# APM32F411 register map
Vendor: Geehy; File version: 2024.11.05
CPU: CM4 r1p0, little endian, 3 interrupt priority bits
Registers are 32-bit, read-write, reset 0x0 unless marked. A register's access mark holds for its fields unless they carry their own. Offsets are from the block's base; [hi:lo] are bit positions.

## TMR10 — General-purpose-timers
Base 0x40014400
Same registers: TMR13 0x40001C00, TMR14 0x40002000
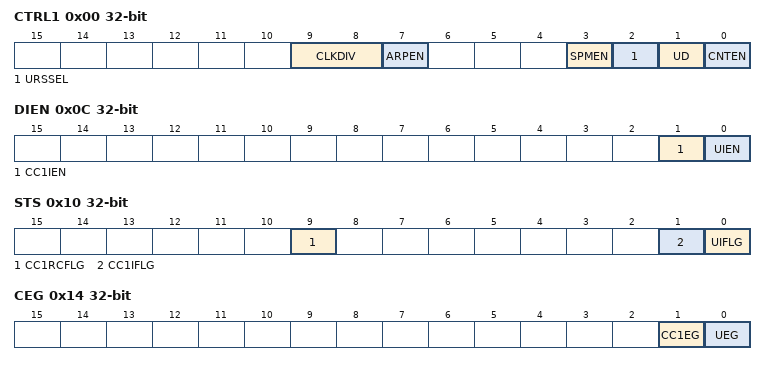
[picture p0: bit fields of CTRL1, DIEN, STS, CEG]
0x00 CTRL1 — control register 1
  [9:8] CLKDIV — Clock division
  [7] ARPEN — Auto-reload preload enable
  [3] SPMEN — Single Pulse Mode Enable
  [2] URSSEL — Update request source
  [1] UD — Update disable
  [0] CNTEN — Counter enable
0x0C DIEN — DMA/Interrupt enable register
  [1] CC1IEN — Capture/Compare 1 interrupt enable
  [0] UIEN — Update interrupt enable
0x10 STS — status register
  [9] CC1RCFLG — Capture/Compare 1 overcapture flag
  [1] CC1IFLG — Capture/compare 1 interrupt flag
  [0] UIFLG — Update interrupt flag
0x14 CEG wo — control event generation register
  [1] CC1EG — Capture/compare 1 generation
  [0] UEG — Update generation
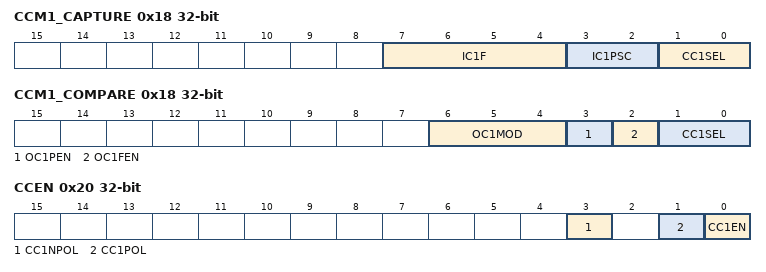
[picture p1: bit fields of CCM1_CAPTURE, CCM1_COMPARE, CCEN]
0x18 CCM1_CAPTURE (alternate view of CCM1_COMPARE) — capture/compare mode register 1 (input mode)
  [7:4] IC1F — Input capture 1 filter
  [3:2] IC1PSC — Input capture 1 prescaler
  [1:0] CC1SEL — Capture/Compare 1 selection
0x18 CCM1_COMPARE — capture/compare mode register 1 (output mode)
  [6:4] OC1MOD — Output Compare 1 mode
  [3] OC1PEN — Output Compare 1 preload enable
  [2] OC1FEN — Output Compare 1 fast enable
  [1:0] CC1SEL — Capture/Compare 1 selection
0x20 CCEN — capture/compare enable register
  [3] CC1NPOL — Capture/Compare 1 output Polarity
  [1] CC1POL — Capture/Compare 1 output Polarity
  [0] CC1EN — Capture/Compare 1 output enable
0x24 CNT — counter
  [15:0] CNT — counter value
0x28 PSC — prescaler
  [15:0] PSC — Prescaler value
0x2C AUTORLD reset 0xFFFF — auto-reload register
  [15:0] AUTORLD — Auto-reload value
0x34 CC1 — capture/compare register 1
  [15:0] CC1 — Capture/Compare 1 value

## TMR11 — General-purpose-timers
Base 0x40014800
Registers as TMR10; these are added or differ:
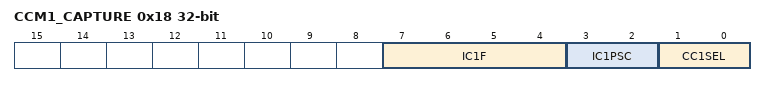
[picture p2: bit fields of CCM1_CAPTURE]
0x18 CCM1_CAPTURE — capture/compare mode register 1 (input mode)
  [7:4] IC1F — Input capture 1 filter
  [3:2] IC1PSC — Input capture 1 prescaler
  [1:0] CC1SEL — Capture/Compare 1 selection
0x50 OPT — option register
  [1:0] RMPSEL — Input 1 remapping capability

## TMR12 — General purpose timers
Base 0x40001800
Same registers: TMR9 0x40014000
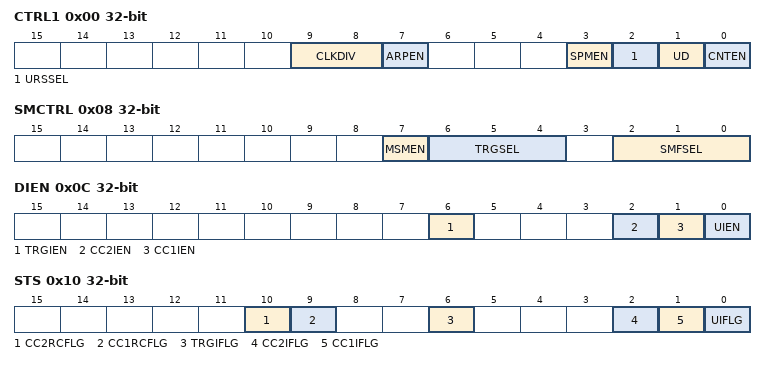
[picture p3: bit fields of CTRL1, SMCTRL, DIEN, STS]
0x00 CTRL1 — control register 1
  [9:8] CLKDIV — Clock division
  [7] ARPEN — Auto-reload preload enable
  [3] SPMEN — One-pulse mode
  [2] URSSEL — Update request source
  [1] UD — Update disable
  [0] CNTEN — Counter enable
0x08 SMCTRL — slave mode control register
  [7] MSMEN — Master/Slave mode
  [6:4] TRGSEL — Trigger selection
  [2:0] SMFSEL — Slave mode selection
0x0C DIEN — DMA/Interrupt enable register
  [6] TRGIEN — Trigger interrupt enable
  [2] CC2IEN — Capture/Compare 2 interrupt enable
  [1] CC1IEN — Capture/Compare 1 interrupt enable
  [0] UIEN — Update interrupt enable
0x10 STS — status register
  [10] CC2RCFLG — Capture/compare 2 overcapture flag
  [9] CC1RCFLG — Capture/Compare 1 overcapture flag
  [6] TRGIFLG — Trigger interrupt flag
  [2] CC2IFLG — Capture/Compare 2 interrupt flag
  [1] CC1IFLG — Capture/compare 1 interrupt flag
  [0] UIFLG — Update interrupt flag
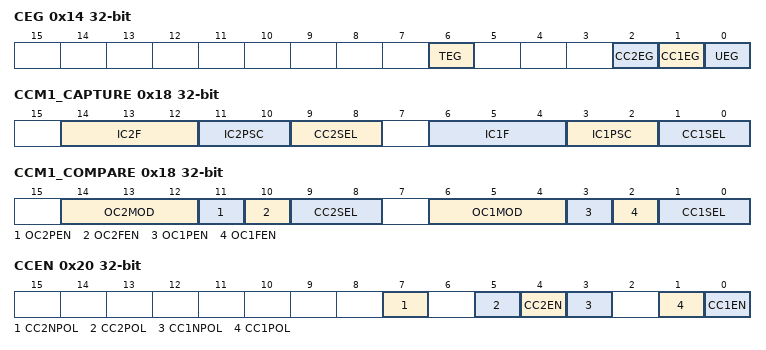
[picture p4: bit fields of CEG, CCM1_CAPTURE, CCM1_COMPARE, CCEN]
0x14 CEG wo — control event generation register
  [6] TEG — Trigger generation
  [2] CC2EG — Capture/compare 2 generation
  [1] CC1EG — Capture/compare 1 generation
  [0] UEG — Update generation
0x18 CCM1_CAPTURE (alternate view of CCM1_COMPARE) — capture/compare mode register 1 (input mode)
  [14:12] IC2F — Input capture 2 filter
  [11:10] IC2PSC — Input capture 2 prescaler
  [9:8] CC2SEL — Capture/Compare 2 selection
  [6:4] IC1F — Input capture 1 filter
  [3:2] IC1PSC — Input capture 1 prescaler
  [1:0] CC1SEL — Capture/Compare 1 selection
0x18 CCM1_COMPARE — capture/compare mode register 1 (output mode)
  [14:12] OC2MOD — Output Compare 2 mode
  [11] OC2PEN — Output Compare 2 preload enable
  [10] OC2FEN — Output Compare 2 fast enable
  [9:8] CC2SEL — Capture/Compare 2 selection
  [6:4] OC1MOD — Output Compare 1 mode
  [3] OC1PEN — Output Compare 1 preload enable
  [2] OC1FEN — Output Compare 1 fast enable
  [1:0] CC1SEL — Capture/Compare 1 selection
0x20 CCEN — capture/compare enable register
  [7] CC2NPOL — Capture/Compare 2 output Polarity
  [5] CC2POL — Capture/Compare 2 output Polarity
  [4] CC2EN — Capture/Compare 2 output enable
  [3] CC1NPOL — Capture/Compare 1 output Polarity
  [1] CC1POL — Capture/Compare 1 output Polarity
  [0] CC1EN — Capture/Compare 1 output enable
0x24 CNT — counter
  [15:0] CNT — counter value
0x28 PSC — prescaler
  [15:0] PSC — Prescaler value
0x2C AUTORLD reset 0xFFFF — auto-reload register
  [15:0] AUTORLD — Auto-reload value
0x34 CC1 — capture/compare register 1
  [15:0] CC1 — Capture/Compare 1 value
0x38 CC2 — capture/compare register 2
  [15:0] CC2 — Capture/Compare 2 value
